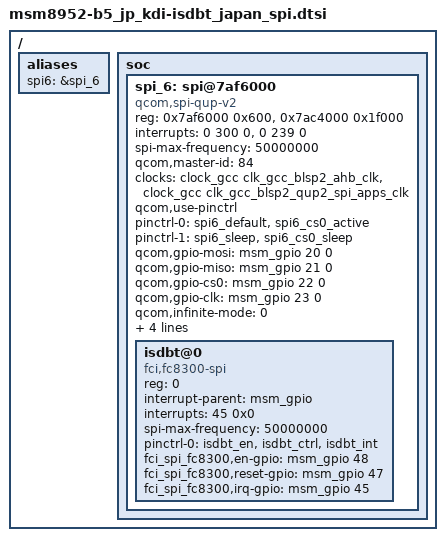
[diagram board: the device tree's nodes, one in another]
/* Copyright (c) 2014, The Linux Foundation. All rights reserved.
 *
 * This program is free software; you can redistribute it and/or modify
 * it under the terms of the GNU General Public License version 2 and
 * only version 2 as published by the Free Software Foundation.
 *
 * This program is distributed in the hope that it will be useful,
 * but WITHOUT ANY WARRANTY; without even the implied warranty of
 * MERCHANTABILITY or FITNESS FOR A PARTICULAR PURPOSE.  See the
 * GNU General Public License for more details.
 */

/ {
	aliases {
		spi6 = &spi_6;
	};
	
	soc {

		spi_6: spi@7af6000 { /* BLSP2 QUP1 */
			status = "ok";
			compatible = "qcom,spi-qup-v2";
			#address-cells = <1>;
			#size-cells = <0>;
			reg-names = "spi_physical", "spi_bam_physical";
			reg = <0x7af6000 0x600>,
				<0x7ac4000 0x1f000>;
			interrupt-names = "spi_irq", "spi_bam_irq";
			interrupts = <0 300 0>, <0 239 0>;
			spi-max-frequency = <50000000>;
			qcom,master-id = <84>;

			clock-names = "iface_clk", "core_clk";
			clocks = <&clock_gcc clk_gcc_blsp2_ahb_clk>,
				<&clock_gcc clk_gcc_blsp2_qup2_spi_apps_clk>;

			/* Assign runtime functions to pins */
			qcom,use-pinctrl;
			pinctrl-names = "spi_default", "spi_sleep";
			pinctrl-0 = <&spi6_default &spi6_cs0_active>;
			pinctrl-1 = <&spi6_sleep &spi6_cs0_sleep>;

			qcom,gpio-mosi = <&msm_gpio 20 0>;
			qcom,gpio-miso = <&msm_gpio 21 0>;
			qcom,gpio-cs0 = <&msm_gpio 22 0>;
			qcom,gpio-clk = <&msm_gpio 23 0>;

			qcom,infinite-mode = <0>;
			qcom,use-bam;
			qcom,ver-reg-exists;
			qcom,bam-consumer-pipe-index = <6>;
			qcom,bam-producer-pipe-index = <7>;
		};
	};	
};

&spi_6 {
	isdbt@0 {
		compatible = "fci,fc8300-spi";

		reg = <0>;
		interrupt-parent = <&msm_gpio>;
		interrupts = <45 0x0>;
		spi-max-frequency = <50000000>;

		pinctrl-names = "isdbt_gpio"; // defined in msm8952-b5_jp_kdi-pinctrl.dtsi
		pinctrl-0 = <&isdbt_en &isdbt_ctrl &isdbt_int>; // defined in msm8952-b5_jp_kdi-pinctrl.dtsi
		fci_spi_fc8300,en-gpio = <&msm_gpio 48 0>;
		fci_spi_fc8300,reset-gpio = <&msm_gpio 47 0>;
		fci_spi_fc8300,irq-gpio = <&msm_gpio 45 0>;
	};
};
